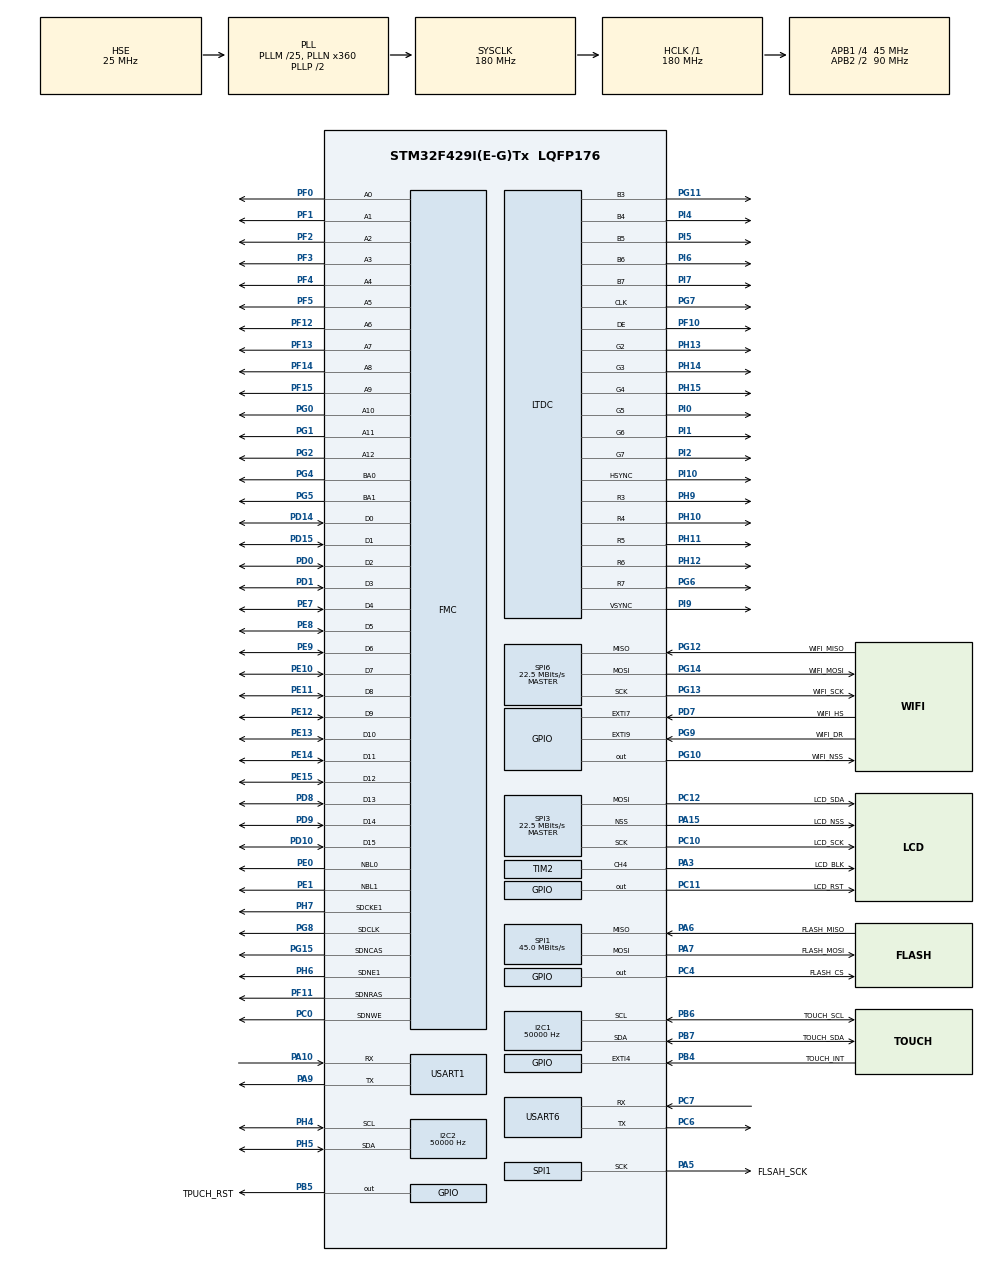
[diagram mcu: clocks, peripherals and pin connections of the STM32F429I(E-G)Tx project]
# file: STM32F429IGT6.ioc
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DMA2D.ColorMode=DMA2D_OUTPUT_RGB565
Dma.MEMTOMEM.0.Direction=DMA_MEMORY_TO_MEMORY
Dma.MEMTOMEM.0.FIFOMode=DMA_FIFOMODE_ENABLE
Dma.MEMTOMEM.0.FIFOThreshold=DMA_FIFO_THRESHOLD_FULL
Dma.MEMTOMEM.0.Instance=DMA2_Stream0
Dma.MEMTOMEM.0.MemBurst=DMA_MBURST_SINGLE
Dma.MEMTOMEM.0.MemDataAlignment=DMA_MDATAALIGN_BYTE
Dma.MEMTOMEM.0.MemInc=DMA_MINC_ENABLE
Dma.MEMTOMEM.0.Mode=DMA_NORMAL
Dma.MEMTOMEM.0.PeriphBurst=DMA_PBURST_SINGLE
Dma.MEMTOMEM.0.PeriphDataAlignment=DMA_PDATAALIGN_BYTE
Dma.MEMTOMEM.0.PeriphInc=DMA_PINC_ENABLE
Dma.MEMTOMEM.0.Priority=DMA_PRIORITY_HIGH
Dma.Request0=MEMTOMEM
FMC.CASLatency1=FMC_SDRAM_CAS_LATENCY_3
FMC.ColumnBitsNumber1=FMC_SDRAM_COLUMN_BITS_NUM_9
FMC.ExitSelfRefreshDelay1=9
FMC.LoadToActiveDelay1=2
FMC.RCDDelay1=2
FMC.RPDelay1=2
FMC.ReadBurst1=FMC_SDRAM_RBURST_ENABLE
FMC.ReadPipeDelay1=FMC_SDRAM_RPIPE_DELAY_1
FMC.RowCycleDelay1=8
FMC.SDClockPeriod1=FMC_SDRAM_CLOCK_PERIOD_2
FMC.SelfRefreshTime1=6
FMC.WriteRecoveryTime1=4
I2C1.ClockSpeed=50000
I2C2.ClockSpeed=50000
LTDC.ActiveH=800
LTDC.ActiveW=480
LTDC.Alpha0_L0=255
LTDC.Alpha0_L1=255
LTDC.Alpha_L0=255
LTDC.Alpha_L1=255
LTDC.FBStartAdress_L0=0xD0000000
LTDC.FBStartAdress_L1=0xD2000000
LTDC.Green_L1=255
LTDC.HBP=15
LTDC.HFP=12
LTDC.HSync=12
LTDC.ImageHeight_L0=800
LTDC.ImageHeight_L1=300
LTDC.ImageWidth_L0=480
LTDC.ImageWidth_L1=360
LTDC.Layers=0
LTDC.PixelFormat_L0=LTDC_PIXEL_FORMAT_RGB565
LTDC.VBP=9
LTDC.VFP=12
LTDC.VSync=10
LTDC.WindowX0_L1=60
LTDC.WindowX1_L0=480
LTDC.WindowX1_L1=420
LTDC.WindowY0_L1=300
LTDC.WindowY1_L0=800
LTDC.WindowY1_L1=600
Mcu.Family=STM32F4
Mcu.Name=STM32F429I(E-G)Tx
Mcu.Package=LQFP176
NVIC.DMA2D_IRQn=true\:0\:0\:false\:false\:true\:true\:true\:true
NVIC.EXTI4_IRQn=true\:0\:0\:false\:false\:true\:true\:true\:true
NVIC.EXTI9_5_IRQn=true\:5\:0\:true\:false\:true\:true\:true\:true
NVIC.LTDC_ER_IRQn=true\:0\:0\:false\:false\:true\:true\:true\:true
NVIC.LTDC_IRQn=true\:0\:0\:false\:false\:true\:true\:true\:true
NVIC.PriorityGroup=NVIC_PRIORITYGROUP_4
NVIC.TIM1_TRG_COM_TIM11_IRQn=true\:0\:0\:false\:false\:true\:true\:true\:true
NVIC.TIM1_UP_TIM10_IRQn=true\:15\:0\:false\:false\:true\:true\:true\:true
NVIC.TIM6_DAC_IRQn=true\:0\:0\:false\:false\:true\:true\:true\:true
NVIC.TIM7_IRQn=true\:0\:0\:false\:false\:true\:true\:true\:true
NVIC.TIM8_TRG_COM_TIM14_IRQn=true\:0\:0\:false\:false\:true\:true\:true\:true
NVIC.TIM8_UP_TIM13_IRQn=true\:0\:0\:false\:false\:true\:true\:true\:true
NVIC.TimeBase=TIM1_UP_TIM10_IRQn
NVIC.TimeBaseIP=TIM1
PA10.Mode=Asynchronous
PA10.Signal=USART1_RX
PA13.Mode=Serial_Wire
PA13.Signal=SYS_JTMS-SWDIO
PA14.Mode=Serial_Wire
PA14.Signal=SYS_JTCK-SWCLK
PA15.GPIO_Label=LCD_NSS
PA15.Mode=NSS_Signal_Hard_Output
PA15.Signal=SPI3_NSS
PA3.GPIO_Label=LCD_BLK
PA3.Signal=S_TIM2_CH4
PA5.GPIO_Label=FLSAH_SCK
PA5.Mode=Full_Duplex_Master
PA5.Signal=SPI1_SCK
PA6.GPIO_Label=FLASH_MISO
PA6.Mode=Full_Duplex_Master
PA6.Signal=SPI1_MISO
PA7.GPIO_Label=FLASH_MOSI
PA7.Mode=Full_Duplex_Master
PA7.Signal=SPI1_MOSI
PA9.Mode=Asynchronous
PA9.Signal=USART1_TX
PB4.GPIO_Label=TOUCH_INT
PB4.Signal=GPXTI4
PB5.GPIO_Label=TPUCH_RST
PB5.Signal=GPIO_Output
PB6.GPIO_Label=TOUCH_SCL
PB6.GPIO_Pu=GPIO_PULLUP
PB6.Mode=I2C
PB6.Signal=I2C1_SCL
PB7.GPIO_Label=TOUCH_SDA
PB7.GPIO_Pu=GPIO_PULLUP
PB7.Mode=I2C
PB7.Signal=I2C1_SDA
PC0.Signal=FMC_SDNWE
PC10.GPIO_Label=LCD_SCK
PC10.Mode=TX_Only_Simplex_Unidirect_Master
PC10.Signal=SPI3_SCK
PC11.GPIO_Label=LCD_RST
PC11.Signal=GPIO_Output
PC12.GPIO_Label=LCD_SDA
PC12.Mode=TX_Only_Simplex_Unidirect_Master
PC12.Signal=SPI3_MOSI
PC4.GPIO_Label=FLASH_CS
PC4.Signal=GPIO_Output
PC6.Mode=Asynchronous
PC6.Signal=USART6_TX
PC7.Mode=Asynchronous
PC7.Signal=USART6_RX
PD0.Signal=FMC_D2_DA2
PD1.Signal=FMC_D3_DA3
PD10.Signal=FMC_D15_DA15
PD14.Signal=FMC_D0_DA0
PD15.Signal=FMC_D1_DA1
PD7.GPIO_Label=WIFI_HS
PD7.Signal=GPXTI7
PD8.Signal=FMC_D13_DA13
PD9.Signal=FMC_D14_DA14
PE0.Signal=FMC_NBL0
PE1.Signal=FMC_NBL1
PE10.Signal=FMC_D7_DA7
PE11.Signal=FMC_D8_DA8
PE12.Signal=FMC_D9_DA9
PE13.Signal=FMC_D10_DA10
PE14.Signal=FMC_D11_DA11
PE15.Signal=FMC_D12_DA12
PE7.Signal=FMC_D4_DA4
PE8.Signal=FMC_D5_DA5
PE9.Signal=FMC_D6_DA6
PF0.Signal=FMC_A0
PF1.Signal=FMC_A1
PF10.GPIO_Speed=GPIO_SPEED_FREQ_VERY_HIGH
PF10.Mode=RGB565
PF10.Signal=LTDC_DE
PF11.Signal=FMC_SDNRAS
PF12.Signal=FMC_A6
PF13.Signal=FMC_A7
PF14.Signal=FMC_A8
PF15.Signal=FMC_A9
PF2.Signal=FMC_A2
PF3.Signal=FMC_A3
PF4.Signal=FMC_A4
PF5.Signal=FMC_A5
PG0.Signal=FMC_A10
PG1.Signal=FMC_A11
PG10.GPIO_Label=WIFI_NSS
PG10.Signal=GPIO_Output
PG11.GPIO_Speed=GPIO_SPEED_FREQ_VERY_HIGH
PG11.Mode=RGB565
PG11.Signal=LTDC_B3
PG12.GPIO_Label=WIFI_MISO
PG12.Mode=Full_Duplex_Master
PG12.Signal=SPI6_MISO
PG13.GPIO_Label=WIFI_SCK
PG13.Mode=Full_Duplex_Master
PG13.Signal=SPI6_SCK
PG14.GPIO_Label=WIFI_MOSI
PG14.Mode=Full_Duplex_Master
PG14.Signal=SPI6_MOSI
PG15.Signal=FMC_SDNCAS
PG2.Signal=FMC_A12
PG4.Signal=FMC_A14_BA0
PG5.Signal=FMC_A15_BA1
PG6.GPIO_Speed=GPIO_SPEED_FREQ_VERY_HIGH
PG6.Mode=RGB565
PG6.Signal=LTDC_R7
PG7.GPIO_Speed=GPIO_SPEED_FREQ_VERY_HIGH
PG7.Mode=RGB565
PG7.Signal=LTDC_CLK
PG8.Signal=FMC_SDCLK
PG9.GPIO_Label=WIFI_DR
PG9.Signal=GPXTI9
PH0/OSC_IN.Mode=HSE-External-Oscillator
PH0/OSC_IN.Signal=RCC_OSC_IN
PH1/OSC_OUT.Mode=HSE-External-Oscillator
PH1/OSC_OUT.Signal=RCC_OSC_OUT
PH10.GPIO_Speed=GPIO_SPEED_FREQ_VERY_HIGH
PH10.Mode=RGB565
PH10.Signal=LTDC_R4
PH11.GPIO_Speed=GPIO_SPEED_FREQ_VERY_HIGH
PH11.Mode=RGB565
PH11.Signal=LTDC_R5
PH12.GPIO_Speed=GPIO_SPEED_FREQ_VERY_HIGH
PH12.Mode=RGB565
PH12.Signal=LTDC_R6
PH13.GPIO_Speed=GPIO_SPEED_FREQ_VERY_HIGH
PH13.Mode=RGB565
PH13.Signal=LTDC_G2
PH14.GPIO_Speed=GPIO_SPEED_FREQ_VERY_HIGH
PH14.Mode=RGB565
PH14.Signal=LTDC_G3
PH15.GPIO_Speed=GPIO_SPEED_FREQ_VERY_HIGH
PH15.Mode=RGB565
PH15.Signal=LTDC_G4
PH4.GPIO_Pu=GPIO_PULLUP
PH4.Mode=I2C
PH4.Signal=I2C2_SCL
PH5.GPIO_Pu=GPIO_PULLUP
PH5.Mode=I2C
PH5.Signal=I2C2_SDA
PH6.Mode=SdramChipSelect2_1
PH6.Signal=FMC_SDNE1
PH7.Mode=SdramChipSelect2_1
PH7.Signal=FMC_SDCKE1
PH9.GPIO_Speed=GPIO_SPEED_FREQ_VERY_HIGH
PH9.Mode=RGB565
PH9.Signal=LTDC_R3
PI0.GPIO_Speed=GPIO_SPEED_FREQ_VERY_HIGH
PI0.Mode=RGB565
PI0.Signal=LTDC_G5
PI1.GPIO_Speed=GPIO_SPEED_FREQ_VERY_HIGH
PI1.Mode=RGB565
PI1.Signal=LTDC_G6
PI10.GPIO_Speed=GPIO_SPEED_FREQ_VERY_HIGH
PI10.Mode=RGB565
PI10.Signal=LTDC_HSYNC
PI2.GPIO_Speed=GPIO_SPEED_FREQ_VERY_HIGH
PI2.Mode=RGB565
PI2.Signal=LTDC_G7
PI4.GPIO_Speed=GPIO_SPEED_FREQ_VERY_HIGH
PI4.Mode=RGB565
PI4.Signal=LTDC_B4
PI5.GPIO_Speed=GPIO_SPEED_FREQ_VERY_HIGH
PI5.Mode=RGB565
PI5.Signal=LTDC_B5
PI6.GPIO_Speed=GPIO_SPEED_FREQ_VERY_HIGH
PI6.Mode=RGB565
PI6.Signal=LTDC_B6
PI7.GPIO_Speed=GPIO_SPEED_FREQ_VERY_HIGH
PI7.Mode=RGB565
PI7.Signal=LTDC_B7
PI9.GPIO_Speed=GPIO_SPEED_FREQ_VERY_HIGH
PI9.Mode=RGB565
PI9.Signal=LTDC_VSYNC
ProjectManager.HeapSize=0x400
ProjectManager.StackSize=0x800
ProjectManager.TargetToolchain=STM32CubeIDE
RCC.48MHZClocksFreq_Value=51428571.428571425
RCC.AHBFreq_Value=180000000
RCC.APB1CLKDivider=RCC_HCLK_DIV4
RCC.APB1Freq_Value=45000000
RCC.APB1TimFreq_Value=90000000
RCC.APB2CLKDivider=RCC_HCLK_DIV2
RCC.APB2Freq_Value=90000000
RCC.APB2TimFreq_Value=180000000
RCC.CortexFreq_Value=180000000
RCC.EXTERNAL_CLOCK_VALUE=25000000
RCC.HCLKFreq_Value=180000000
RCC.HSE_VALUE=25000000
RCC.HSI_VALUE=16000000
RCC.LSE_VALUE=32768
RCC.PLLM=25
RCC.PLLN=360
RCC.PLLQ=7
RCC.PLLSAIN=104
RCC.PLLSourceVirtual=RCC_PLLSOURCE_HSE
RCC.SYSCLKFreq_VALUE=180000000
RCC.SYSCLKSource=RCC_SYSCLKSOURCE_PLLCLK
RCC.VCOOutputFreq_Value=360000000
SH.FMC_A0.0=FMC_A0,13b-sda1
SH.FMC_A1.0=FMC_A1,13b-sda1
SH.FMC_A10.0=FMC_A10,13b-sda1
SH.FMC_A11.0=FMC_A11,13b-sda1
SH.FMC_A12.0=FMC_A12,13b-sda1
SH.FMC_A14_BA0.0=FMC_BA0,FourSdramBanks1
SH.FMC_A15_BA1.0=FMC_BA1,FourSdramBanks1
SH.FMC_A2.0=FMC_A2,13b-sda1
SH.FMC_A3.0=FMC_A3,13b-sda1
SH.FMC_A4.0=FMC_A4,13b-sda1
SH.FMC_A5.0=FMC_A5,13b-sda1
SH.FMC_A6.0=FMC_A6,13b-sda1
SH.FMC_A7.0=FMC_A7,13b-sda1
SH.FMC_A8.0=FMC_A8,13b-sda1
SH.FMC_A9.0=FMC_A9,13b-sda1
SH.FMC_D0_DA0.0=FMC_D0,sd-16b-d1
SH.FMC_D10_DA10.0=FMC_D10,sd-16b-d1
SH.FMC_D11_DA11.0=FMC_D11,sd-16b-d1
SH.FMC_D12_DA12.0=FMC_D12,sd-16b-d1
SH.FMC_D13_DA13.0=FMC_D13,sd-16b-d1
SH.FMC_D14_DA14.0=FMC_D14,sd-16b-d1
SH.FMC_D15_DA15.0=FMC_D15,sd-16b-d1
SH.FMC_D1_DA1.0=FMC_D1,sd-16b-d1
SH.FMC_D2_DA2.0=FMC_D2,sd-16b-d1
SH.FMC_D3_DA3.0=FMC_D3,sd-16b-d1
SH.FMC_D4_DA4.0=FMC_D4,sd-16b-d1
SH.FMC_D5_DA5.0=FMC_D5,sd-16b-d1
SH.FMC_D6_DA6.0=FMC_D6,sd-16b-d1
SH.FMC_D7_DA7.0=FMC_D7,sd-16b-d1
SH.FMC_D8_DA8.0=FMC_D8,sd-16b-d1
SH.FMC_D9_DA9.0=FMC_D9,sd-16b-d1
SH.FMC_NBL0.0=FMC_NBL0,Sd2ByteEnable1
SH.FMC_NBL1.0=FMC_NBL1,Sd2ByteEnable1
SH.FMC_SDCLK.0=FMC_SDCLK,13b-sda1
SH.FMC_SDNCAS.0=FMC_SDNCAS,13b-sda1
SH.FMC_SDNRAS.0=FMC_SDNRAS,13b-sda1
SH.FMC_SDNWE.0=FMC_SDNWE,13b-sda1
SH.S_TIM2_CH4.0=TIM2_CH4,PWM Generation4 CH4
SPI1.BaudRatePrescaler=SPI_BAUDRATEPRESCALER_2
SPI1.CalculateBaudRate=45.0 MBits/s
SPI1.Direction=SPI_DIRECTION_2LINES
SPI1.Mode=SPI_MODE_MASTER
SPI1.VirtualType=VM_MASTER
SPI3.BaudRatePrescaler=SPI_BAUDRATEPRESCALER_2
SPI3.CalculateBaudRate=22.5 MBits/s
SPI3.Direction=SPI_DIRECTION_2LINES
SPI3.Mode=SPI_MODE_MASTER
SPI3.VirtualNSS=VM_NSSHARD
SPI3.VirtualType=VM_MASTER
SPI6.BaudRatePrescaler=SPI_BAUDRATEPRESCALER_4
SPI6.CLKPhase=SPI_PHASE_2EDGE
SPI6.CLKPolarity=SPI_POLARITY_HIGH
SPI6.CalculateBaudRate=22.5 MBits/s
SPI6.Direction=SPI_DIRECTION_2LINES
SPI6.Mode=SPI_MODE_MASTER
SPI6.VirtualType=VM_MASTER
TIM10.AutoReloadPreload=TIM_AUTORELOAD_PRELOAD_ENABLE
TIM10.Period=179
TIM10.Prescaler=19999
TIM11.AutoReloadPreload=TIM_AUTORELOAD_PRELOAD_ENABLE
TIM11.Period=179
TIM11.Prescaler=49999
TIM13.AutoReloadPreload=TIM_AUTORELOAD_PRELOAD_ENABLE
TIM13.Period=179
TIM13.Prescaler=9999
TIM14.AutoReloadPreload=TIM_AUTORELOAD_PRELOAD_ENABLE
TIM14.Period=179
TIM14.Prescaler=99
TIM2.AutoReloadPreload=TIM_AUTORELOAD_PRELOAD_DISABLE
TIM2.Channel-PWM\ Generation4\ CH4=TIM_CHANNEL_4
TIM2.ClockDivision=TIM_CLOCKDIVISION_DIV1
TIM2.CounterMode=TIM_COUNTERMODE_UP
TIM2.Period=4499
TIM2.Prescaler=0
TIM6.AutoReloadPreload=TIM_AUTORELOAD_PRELOAD_ENABLE
TIM6.Period=179
TIM6.Prescaler=999
TIM7.AutoReloadPreload=TIM_AUTORELOAD_PRELOAD_ENABLE
TIM7.Period=179
TIM7.Prescaler=4999
USART1.VirtualMode=VM_ASYNC
USART6.VirtualMode=VM_ASYNC
VP_CRC_VS_CRC.Mode=CRC_Activate
VP_DMA2D_VS_DMA2D.Mode=DMA2D_Activate
VP_SYS_VS_tim1.Mode=TIM1
VP_TIM10_VS_ClockSourceINT.Mode=Enable_Timer
VP_TIM11_VS_ClockSourceINT.Mode=Enable_Timer
VP_TIM13_VS_ClockSourceINT.Mode=Enable_Timer
VP_TIM14_VS_ClockSourceINT.Mode=Enable_Timer
VP_TIM6_VS_ClockSourceINT.Mode=Enable_Timer
VP_TIM7_VS_ClockSourceINT.Mode=Enable_Timer
board=custom

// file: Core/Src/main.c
/* USER CODE BEGIN Header */
/**
  ******************************************************************************
  * @file           : main.c
  * @brief          : Main program body
  ******************************************************************************
  * @attention
  *
  * Copyright (c) 2026 STMicroelectronics.
  * All rights reserved.
  *
  * This software is licensed under terms that can be found in the LICENSE file
  * in the root directory of this software component.
  * If no LICENSE file comes with this software, it is provided AS-IS.
  *
  ******************************************************************************
  */
/* USER CODE END Header */
#include "main.h"
#include "crc.h"
#include "dma.h"
#include "dma2d.h"
#include "i2c.h"
#include "ltdc.h"
#include "spi.h"
#include "tim.h"
#include "usart.h"
#include "gpio.h"
#include "fmc.h"

/* USER CODE BEGIN Includes */
#include "bsp_lcd.h"
#include "board_lvgl.h"
#include "board_model.h"
#include "g474_remote.h"
#include "parameter_manager.h"
#include "uf4com.h"
#include "uf4com_usrt.h"
#include "w25qxx_port.h"

/* USER CODE END Includes */

void SystemClock_Config(void);
/* USER CODE BEGIN PFP */
static void Application_Init(void);
static void Application_Process(void);

/* USER CODE END PFP */

/* USER CODE BEGIN 0 */
static void Application_Init(void)
{
  LCD_Init();
  Board_Model_InitDefaults();
  (void)W25Qxx_Init();
  UF4_ParameterManager_Init();
  /* ESP32 service is intentionally out of the current bring-up scope.  A
   * previously persisted WIFI/BLE selection must not lock the local F429
   * touch controls or prevent the F429↔G474 power link from being tested. */
  {
    ui_setting_t *esp32_mode =
        Board_Model_FindSetting(UI_SETTING_ID_ESP32_START_MODE);
    if (esp32_mode != NULL)
      esp32_mode->current = UI_ESP32_START_NONE;
  }
  UF4_Init(UF4_UART_Tx, &huart6);
  G474_Remote_Init();
  UF4_UART_Init();
  Board_LVGL_Init();
}

static void Application_Process(void)
{
  uint32_t now_ms = HAL_GetTick();

  UF4_UART_Process();
  UF4_ProcessMs(now_ms);
  G474_Remote_Process();
  UF4_ParameterManager_Process();

  Board_LVGL_Process();
}

/* USER CODE END 0 */

int main(void)
{

  /* MCU Configuration--------------------------------------------------------*/

  /* Reset of all peripherals, Initializes the Flash interface and the Systick. */
  HAL_Init();

  /* Configure the system clock */
  SystemClock_Config();

  /* Initialize all configured peripherals */
  MX_GPIO_Init();
  MX_DMA_Init();
  MX_DMA2D_Init();
  MX_FMC_Init();
  MX_I2C1_Init();
  MX_LTDC_Init();
  MX_TIM6_Init();
  MX_USART1_UART_Init();
  MX_SPI3_Init();
  MX_SPI6_Init();
  MX_USART6_UART_Init();
  MX_TIM7_Init();
  MX_TIM10_Init();
  MX_TIM11_Init();
  MX_TIM13_Init();
  MX_TIM14_Init();
  MX_TIM2_Init();
  MX_I2C2_Init();
  MX_SPI1_Init();
  MX_CRC_Init();
  /* USER CODE BEGIN 2 */

  Application_Init();

  /* USER CODE END 2 */

  /* Infinite loop */
  while (1)
  {

    /* USER CODE BEGIN 3 */
    Application_Process();
    HAL_Delay(1U);

  }
  /* USER CODE END 3 */
}

void SystemClock_Config(void)
{
  RCC_OscInitTypeDef RCC_OscInitStruct = {0};
  RCC_ClkInitTypeDef RCC_ClkInitStruct = {0};

  /** Configure the main internal regulator output voltage
  */
  __HAL_RCC_PWR_CLK_ENABLE();
  __HAL_PWR_VOLTAGESCALING_CONFIG(PWR_REGULATOR_VOLTAGE_SCALE1);

  /** Initializes the RCC Oscillators according to the specified parameters
  * in the RCC_OscInitTypeDef structure.
  */
  RCC_OscInitStruct.OscillatorType = RCC_OSCILLATORTYPE_HSE;
  RCC_OscInitStruct.HSEState = RCC_HSE_ON;
  RCC_OscInitStruct.PLL.PLLState = RCC_PLL_ON;
  RCC_OscInitStruct.PLL.PLLSource = RCC_PLLSOURCE_HSE;
  RCC_OscInitStruct.PLL.PLLM = 25;
  RCC_OscInitStruct.PLL.PLLN = 360;
  RCC_OscInitStruct.PLL.PLLP = RCC_PLLP_DIV2;
  RCC_OscInitStruct.PLL.PLLQ = 7;
  if (HAL_RCC_OscConfig(&RCC_OscInitStruct) != HAL_OK)
  {
    Error_Handler();
  }

  /** Activate the Over-Drive mode
  */
  if (HAL_PWREx_EnableOverDrive() != HAL_OK)
  {
    Error_Handler();
  }

  /** Initializes the CPU, AHB and APB buses clocks
  */
  RCC_ClkInitStruct.ClockType = RCC_CLOCKTYPE_HCLK|RCC_CLOCKTYPE_SYSCLK
                              |RCC_CLOCKTYPE_PCLK1|RCC_CLOCKTYPE_PCLK2;
  RCC_ClkInitStruct.SYSCLKSource = RCC_SYSCLKSOURCE_PLLCLK;
  RCC_ClkInitStruct.AHBCLKDivider = RCC_SYSCLK_DIV1;
  RCC_ClkInitStruct.APB1CLKDivider = RCC_HCLK_DIV4;
  RCC_ClkInitStruct.APB2CLKDivider = RCC_HCLK_DIV2;

  if (HAL_RCC_ClockConfig(&RCC_ClkInitStruct, FLASH_LATENCY_5) != HAL_OK)
  {
    Error_Handler();
  }
}

void HAL_TIM_PeriodElapsedCallback(TIM_HandleTypeDef *htim)
{
  if (htim->Instance == TIM1)
  {
    HAL_IncTick();
  }
}

void Error_Handler(void)
{
  __disable_irq();
  while (1)
  {
  }
}
